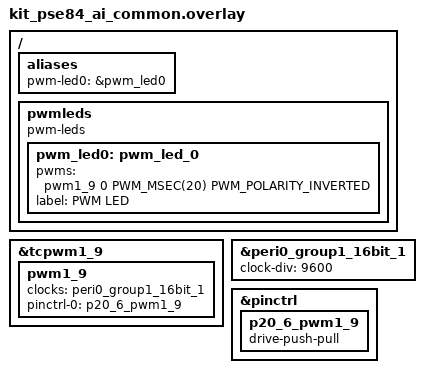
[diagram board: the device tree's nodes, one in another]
/*
 * Copyright (c) 2026 Infineon Technologies AG,
 * or an affiliate of Infineon Technologies AG.
 *
 * SPDX-License-Identifier: Apache-2.0
 */

#include <zephyr/dt-bindings/pwm/pwm.h>
#include <zephyr/dt-bindings/pwm/pwm_ifx_tcpwm.h>

/ {
	aliases {
		pwm-led0 = &pwm_led0;
	};

	pwmleds {
		compatible = "pwm-leds";

		pwm_led0: pwm_led_0 {
			pwms = <&pwm1_9 0 PWM_MSEC(20) PWM_POLARITY_INVERTED>;
			label = "PWM LED";
		};

		status = "okay";
	};
};

&tcpwm1_9 {
	status = "okay";

	pwm1_9: pwm1_9 {
		status = "okay";
		clocks = <&peri0_group1_16bit_1>;
		pinctrl-0 = <&p20_6_pwm1_9>;
		pinctrl-names = "default";
	};
};

&peri0_group1_16bit_1 {
	status = "okay";
	clock-div = <9600>;
};

&pinctrl {
	p20_6_pwm1_9: p20_6_pwm1_9 {
		drive-push-pull;
	};
};
